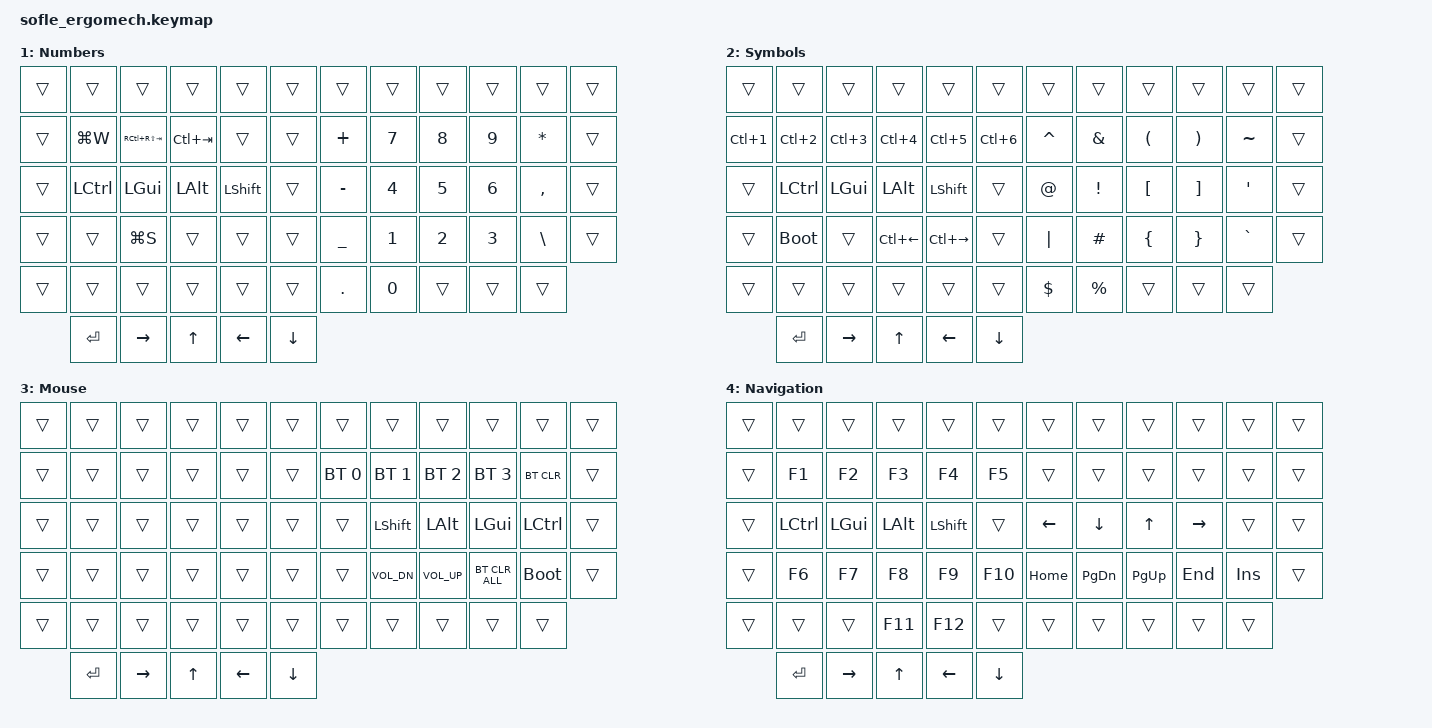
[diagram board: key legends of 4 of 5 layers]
/*
 * Copyright (c) 2022 The ZMK Contributors
 *
 * SPDX-License-Identifier: MIT
 */

#include <behaviors.dtsi>
#include <dt-bindings/zmk/bt.h>
#include <dt-bindings/zmk/ext_power.h>
#include <dt-bindings/zmk/keys.h>
#include <dt-bindings/zmk/pointing.h> // Include for mouse keys

// Layers
#define L_DEFAULT 0
#define L_NUM     1
#define L_SYM     2
#define L_MOUSE   3
#define L_NAV     4

// Home row mods macro
#define HRML(k1,k2,k3,k4) &ht LCTRL k1  &ht LGUI k2  &ht LALT k3  &ht LSHFT k4
#define HRMR(k1,k2,k3,k4) &ht RSHFT k1  &ht LALT k2  &ht LGUI k3  &ht LCTRL k4

/ {
    behaviors {
        ht: hold_tap {
            compatible = "zmk,behavior-hold-tap";
            #binding-cells = <2>;
            flavor = "tap-preferred";
            // Tapping term can be adjusted, using the value from old.keymap
            tapping-term-ms = <180>;
            bindings = <&kp>, <&kp>;
        };
    };

    combos {
        compatible = "zmk,combos";
        combo_capsword {
            timeout-ms = <50>;
            // Adjust key positions for Sofle layout if needed. Assuming HRML/R keys map to Sofle home row:
            // Old pos 21, 22 -> Sofle S, D -> Sofle indices 26, 27
            key-positions = <26 27>;
            layers = <L_DEFAULT>;
            bindings = <&caps_word>;
        };
        combo_tab {
            timeout-ms = <50>;
            // Old pos 22, 23 -> Sofle D, F -> Sofle indices 27, 28
            key-positions = <27 28>;
            layers = <L_DEFAULT>;
            bindings = <&kp TAB>;
        };
        combo_del {
            timeout-ms = <50>;
            // Old pos 23, 24 -> Sofle F, G -> Sofle indices 28, 29
            key-positions = <28 29>;
            layers = <L_DEFAULT>;
            bindings = <&kp DEL>;
        };
        combo_eq {
            timeout-ms = <50>;
            // Old pos 26, 27 -> Sofle J, K -> Sofle indices 32, 33
            key-positions = <32 33>;
            layers = <L_DEFAULT>;
            bindings = <&kp EQUAL>;
        };
        combo_dquote {
            timeout-ms = <50>;
            // Old pos 27, 28 -> Sofle K, L -> Sofle indices 33, 34
            key-positions = <33 34>;
            layers = <L_DEFAULT>;
            bindings = <&kp DOUBLE_QUOTES>;
        };
    };


    keymap {
        compatible = "zmk,keymap";

        default_layer {
            label = "Default";
            // Based on mapping from 34-key layout (Ferris Sweep style) to 58-key Sofle
            // Fill unused keys with &none
            bindings = <
// | LTop1 | LTop2 | LTop3 | LTop4 | LTop5 | LTop6 |   | RTop1 | RTop2 | RTop3 | RTop4 | RTop5 | RTop6 |
   &none   &none   &none   &none   &none   &none         &none   &none   &none   &none   &none   &none
// | LMid1 | LMid2 | LMid3 | LMid4 | LMid5 | LMid6 |   | RMid1 | RMid2 | RMid3 | RMid4 | RMid5 | RMid6 |
   &none   &kp Q   &kp W   &kp E   &kp R   &kp T         &kp Y   &kp U   &kp I   &kp O   &kp P   &none
// | LHome1| LHome2| LHome3| LHome4| LHome5| LHome6|   | RHome1| RHome2| RHome3| RHome4| RHome5| RHome6|
   &none   HRML(A,  S,     D,     F)       &kp G         &kp H   HRMR(J,  K,     L,   SEMI) &none
// | LBot1 | LBot2 | LBot3 | LBot4 | LBot5 | LBot6 |   | RBot1 | RBot2 | RBot3 | RBot4 | RBot5 | RBot6 |
   &none   &kp Z   &kp X   &kp C   &kp V   &kp B         &kp N   &kp M   &kp COMMA &kp DOT &kp FSLH &none
// | LOuter| LThumb1| LThumb2| LThumb3| LThumb4|         | RThumb1| RThumb2| RThumb3| RThumb4| ROuter |
   &none   &none    &none    &lt L_NUM ESC    &lt L_SYM SPACE  &none     &none  &lt L_MOUSE BSPC  &lt L_NAV RET  &none  &none
            // 5-Directional Switch Bindings (Append after standard keys)
            &kp RET   &kp RIGHT  &kp UP   &kp LEFT  &kp DOWN
            >;

            // Rotary Encoder Bindings
            sensor-bindings = <&inc_dec_kp UP DOWN>;
        };

        num_layer {
            label = "Numbers";
            // Fill unused keys with &trans
            bindings = <
   &trans  &trans    &trans          &trans      &trans    &trans        &trans        &trans        &trans      &trans     &trans     &trans
   &trans  &kp LG(W) &kp RC(RS(TAB)) &kp LC(TAB) &trans    &trans        &kp PLUS      &kp N7        &kp N8      &kp N9     &kp ASTRK  &trans
   &trans  &kp LCTRL &kp LGUI        &kp LALT    &kp LSHFT &trans        &kp MINUS     &kp N4        &kp N5      &kp N6     &kp COMMA  &trans
   &trans  &trans    &kp LG(S)       &trans      &trans    &trans        &kp UNDER     &kp N1        &kp N2      &kp N3     &kp BSLH   &trans
   &trans  &trans    &trans          &trans      &trans    &trans        &kp DOT       &kp N0        &trans      &trans     &trans
            // 5-Directional Switch Bindings
            &kp RET   &kp RIGHT  &kp UP   &kp LEFT  &kp DOWN
            >;
            // Rotary Encoder Bindings
            sensor-bindings = <&inc_dec_kp UP DOWN>;
        };

        sym_layer {
            label = "Symbols";
            bindings = <
   &trans  &trans        &trans         &trans       &trans         &trans           &trans      &trans       &trans     &trans     &trans       &trans
   &kp LC(N1)  &kp LC(N2)    &kp LC(N3)     &kp LC(N4)   &kp LC(N5)     &kp LC(N6)   &kp CARET   &kp AMPS     &kp LPAR   &kp RPAR   &kp TILDE    &trans
   &trans  &kp LCTRL     &kp LGUI       &kp LALT     &kp LSHFT      &trans           &kp AT      &kp EXCL     &kp LBKT   &kp RBKT   &kp SQT      &trans
   &trans  &bootloader   &trans         &kp LC(LEFT) &kp LC(RIGHT)  &trans           &kp PIPE    &kp HASH     &kp LBRC   &kp RBRC   &kp GRAVE    &trans
   &trans  &trans        &trans         &trans       &trans           &trans         &kp DLLR    &kp PRCNT     &trans     &trans     &trans
            // 5-Directional Switch Bindings
            &kp RET   &kp RIGHT  &kp UP   &kp LEFT  &kp DOWN
            >;
            // Rotary Encoder Bindings
            sensor-bindings = <&inc_dec_kp UP DOWN>;
        };

        mouse_layer {
            label = "Mouse";
            bindings = <
   &trans  &trans          &trans          &trans           &trans         &trans         &trans        &trans        &trans        &trans         &trans      &trans
   &trans  &trans          &trans          &trans           &trans         &trans         &bt BT_SEL 0  &bt BT_SEL 1  &bt BT_SEL 2  &bt BT_SEL 3   &bt BT_CLR  &trans
   &trans  &trans          &trans          &trans           &trans         &trans         &trans        &kp LSHFT     &kp LALT      &kp LGUI       &kp LCTRL   &trans
   &trans  &trans          &trans          &trans           &trans         &trans         &trans        &kp C_VOL_DN  &kp C_VOL_UP  &bt BT_CLR_ALL &bootloader &trans
   &trans  &trans          &trans          &trans           &trans         &trans         &trans        &trans        &trans        &trans         &trans
            // 5-Directional Switch Bindings
            &kp RET   &kp RIGHT  &kp UP   &kp LEFT  &kp DOWN
            >;
            // Rotary Encoder Bindings
            sensor-bindings = <&inc_dec_kp UP DOWN>;
        };

        nav_layer {
            label = "Navigation";
            bindings = <
   &trans  &trans    &trans    &trans    &trans     &trans        &trans    &trans     &trans     &trans     &trans       &trans
   &trans  &kp F1    &kp F2    &kp F3    &kp F4     &kp F5        &trans    &trans     &trans     &trans     &trans       &trans
   &trans  &kp LCTRL &kp LGUI  &kp LALT  &kp LSHFT  &trans        &kp LEFT  &kp DOWN   &kp UP     &kp RIGHT  &trans       &trans
   &trans  &kp F6    &kp F7    &kp F8    &kp F9     &kp F10       &kp HOME  &kp PG_DN  &kp PG_UP  &kp END    &kp INS      &trans
   &trans  &trans    &trans    &kp F11   &kp F12    &trans        &trans     &trans     &trans     &trans     &trans
            // 5-Directional Switch Bindings
            &kp RET   &kp RIGHT  &kp UP   &kp LEFT  &kp DOWN
            >;
            // Rotary Encoder Bindings
            sensor-bindings = <&inc_dec_kp UP DOWN>;
        };
    };
};
